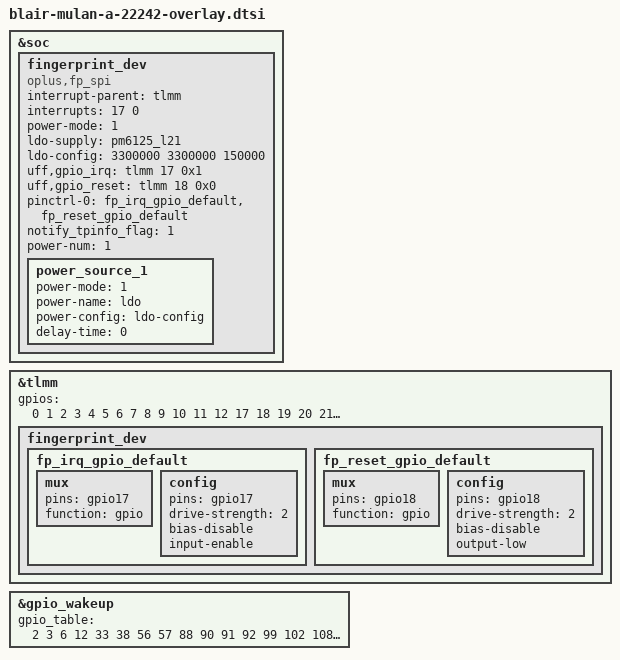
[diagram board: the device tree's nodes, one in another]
//#ifdef OPLUS_FEATURE_CHG_BASIC
#include "charge/oplus_charge_mulan-a-22241.dtsi"
//#endif

&soc {
	// #ifdef OPLUS_FEATURE_UFF_FINGERPRINT
	fingerprint_dev {
		status = "ok";
		compatible = "oplus,fp_spi";
		interrupt-parent = <&tlmm>;
		interrupts = <17 0>;
		power-mode = <1> ; /*0: power mode not set, 1: ldo power, 2: gpio power, 3: auto power */
		ldo-supply = <&pm6125_l21>;
		ldo-config = <3300000 3300000 150000>;
		uff,gpio_irq = <&tlmm 17 0x1>;
		uff,gpio_reset = <&tlmm 18 0x0>;
		pinctrl-names = "default";
		pinctrl-0 = <&fp_irq_gpio_default>,<&fp_reset_gpio_default>;
		notify_tpinfo_flag = <1>;
		power-num = <1>;
		power_source_1 {
			power-mode = <1>;
			power-name = "ldo";
			power-config = "ldo-config";
			delay-time = <0>;
		};
	};
	//#endif /*OPLUS_FEATURE_UFF_FINGERPRINT*/
};

&tlmm {
	/* blair_reserved_gpios[] = {13, 14, 15, 16, 17, 45, 46, 48, 56, 57, -1}; */
	/* delete gpio 17 45 46 */
	gpios = /bits/ 16 <
			0 1 2 3 4 5 6 7 8 9
			10 11 12             17 18 19
			20 21 22 23 24 25 26 27 28 29
			30 31 32 33 34 35 36 37 38 39
			40 41 42 43 44 45 46 47    49
			50 51 52 53 54 55       58 59
			60 61 62 63 64 65 66 67 68 69
			70 71 72 73 74 75 76 77 78 79
			80 81 82 83 84 85 86 87 88 89
			90 91 92 93 94 95 96 97 98 99
			100 101 102 103 104 105 106 107 108 109
			110 111 112 113 114 115 116 117 118 119
			120 121 122 123 124 125 126 127 128 129
			130 131 132 133 134 135 136 137 138 139
			140 141 142 143 144 145 146 147 148 149
			150 151 152 153 154 155 156
			>;
	// #ifdef OPLUS_FEATURE_UFF_FINGERPRINT
	fingerprint_dev{
		fp_irq_gpio_default: fp_irq_gpio_default {
			mux {
				pins = "gpio17";
				function = "gpio";
			};
			config {
				pins = "gpio17";
				drive-strength = <2>;
				bias-disable;
				input-enable;
			};
		};

		fp_reset_gpio_default: fp_reset_gpio_default {
			mux {
				pins = "gpio18";
				function = "gpio";
			};
			config {
				pins = "gpio18";
				drive-strength = <2>;
				bias-disable;
				output-low;
			};
		};
	};
	//#endif /*OPLUS_FEATURE_UFF_FINGERPRINT*/
};

&gpio_wakeup {
	gpio_table = <2 3 6 12 33 38 56 57 88 90 91 92 99 102 108 113 114 115 116
		      7 8 9 48 51 59 84 85 86 107 117 118 152 153 154 155>;
};
